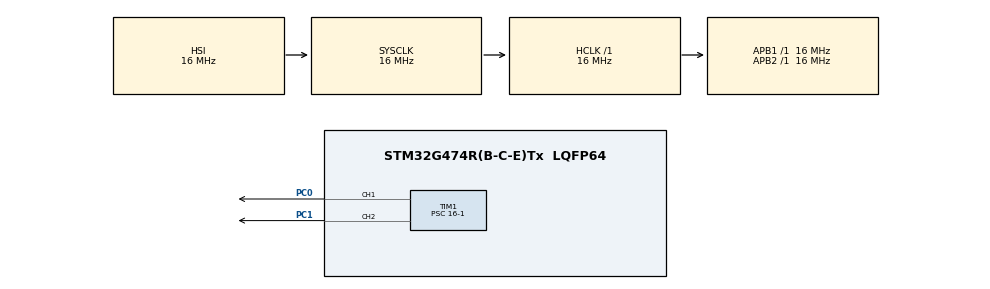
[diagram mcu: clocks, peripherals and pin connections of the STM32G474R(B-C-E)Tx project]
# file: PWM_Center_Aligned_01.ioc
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Mcu.Family=STM32G4
Mcu.Name=STM32G474R(B-C-E)Tx
Mcu.Package=LQFP64
NVIC.PriorityGroup=NVIC_PRIORITYGROUP_4
PC0.Signal=S_TIM1_CH1
PC1.Signal=S_TIM1_CH2
ProjectManager.HeapSize=0x200
ProjectManager.StackSize=0x400
ProjectManager.TargetToolchain=STM32CubeIDE
RCC.ADC12Freq_Value=16000000
RCC.ADC345Freq_Value=16000000
RCC.AHBFreq_Value=16000000
RCC.APB1Freq_Value=16000000
RCC.APB1TimFreq_Value=16000000
RCC.APB2Freq_Value=16000000
RCC.APB2TimFreq_Value=16000000
RCC.CortexFreq_Value=16000000
RCC.EXTERNAL_CLOCK_VALUE=12288000
RCC.HCLKFreq_Value=16000000
RCC.HSE_VALUE=24000000
RCC.HSI48_VALUE=48000000
RCC.HSI_VALUE=16000000
RCC.LSE_VALUE=32768
RCC.PLLM=RCC_PLLM_DIV4
RCC.PLLN=85
RCC.RTCClockSelection=RCC_RTCCLKSOURCE_LSE
RCC.SYSCLKFreq_VALUE=16000000
RCC.USBFreq_Value=170000000
RCC.VCOOutputFreq_Value=340000000
SH.S_TIM1_CH1.0=TIM1_CH1,PWM Generation1 CH1
SH.S_TIM1_CH2.0=TIM1_CH2,PWM Generation2 CH2
TIM1.AutoReloadPreload=TIM_AUTORELOAD_PRELOAD_ENABLE
TIM1.Channel-PWM\ Generation1\ CH1=TIM_CHANNEL_1
TIM1.Channel-PWM\ Generation2\ CH2=TIM_CHANNEL_2
TIM1.CounterMode=TIM_COUNTERMODE_CENTERALIGNED3
TIM1.PeriodNoDither=1000
TIM1.Prescaler=16-1
VP_SYS_VS_DBSignals.Mode=DisableDeadBatterySignals
VP_TIM1_VS_ClockSourceINT.Mode=Internal
board=NUCLEO-G474RE

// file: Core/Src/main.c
/* USER CODE BEGIN Header */
/**
  ******************************************************************************
  * @file           : main.c
  * @brief          : Main program body
  ******************************************************************************
  * @attention
  *
  * Copyright (c) 2026 STMicroelectronics.
  * All rights reserved.
  *
  * This software is licensed under terms that can be found in the LICENSE file
  * in the root directory of this software component.
  * If no LICENSE file comes with this software, it is provided AS-IS.
  *
  ******************************************************************************
	Hardware: NUCLEO-G474RE
	Objetivo: Alterar o alinhamento do PWM para o centro.

	Notas:
		Nas configurações do timer, selecione em "Counter Mode" a opção "Center Aligned mode3".
		E habilite o "auto-reload preload".

		f_tim_clk = 16 MHz
		PSC = 16-1 -> f_pwm = 1MHz
		ARR = 1000 -> f_pwm = f_pwm/(ARR/2) = 500Hz
		Conta até o valor de ARR.
  */
/* USER CODE END Header */
#include "main.h"

/* USER CODE BEGIN PD */
uint32_t dc1, dc2;
/* USER CODE END PD */

TIM_HandleTypeDef htim1;

void SystemClock_Config(void);
static void MX_GPIO_Init(void);
static void MX_TIM1_Init(void);

int main(void)
{

  /* MCU Configuration--------------------------------------------------------*/

  /* Reset of all peripherals, Initializes the Flash interface and the Systick. */
  HAL_Init();

  /* Configure the system clock */
  SystemClock_Config();

  /* Initialize all configured peripherals */
  MX_GPIO_Init();
  MX_TIM1_Init();
  /* USER CODE BEGIN 2 */

  // Inicializando o timer
  HAL_TIM_PWM_Start(&htim1, TIM_CHANNEL_1);
  HAL_TIM_PWM_Start(&htim1, TIM_CHANNEL_2);

  dc1 = 500;
  dc2 = dc2/2;

  /* USER CODE END 2 */

  /* Infinite loop */
  while (1)
  {

    /* USER CODE BEGIN 3 */
	  TIM1->CCR1 = dc1; // contador do canal 1
	  TIM1->CCR2 = dc2; // contador do canal 2

	  // Obs.: Atrubua valores as variaveis dc1 e dc2 pelo debug.
  }
  /* USER CODE END 3 */
}

void SystemClock_Config(void)
{
  RCC_OscInitTypeDef RCC_OscInitStruct = {0};
  RCC_ClkInitTypeDef RCC_ClkInitStruct = {0};

  /** Configure the main internal regulator output voltage
  */
  HAL_PWREx_ControlVoltageScaling(PWR_REGULATOR_VOLTAGE_SCALE1);

  /** Initializes the RCC Oscillators according to the specified parameters
  * in the RCC_OscInitTypeDef structure.
  */
  RCC_OscInitStruct.OscillatorType = RCC_OSCILLATORTYPE_HSI;
  RCC_OscInitStruct.HSIState = RCC_HSI_ON;
  RCC_OscInitStruct.HSICalibrationValue = RCC_HSICALIBRATION_DEFAULT;
  RCC_OscInitStruct.PLL.PLLState = RCC_PLL_NONE;
  if (HAL_RCC_OscConfig(&RCC_OscInitStruct) != HAL_OK)
  {
    Error_Handler();
  }

  /** Initializes the CPU, AHB and APB buses clocks
  */
  RCC_ClkInitStruct.ClockType = RCC_CLOCKTYPE_HCLK|RCC_CLOCKTYPE_SYSCLK
                              |RCC_CLOCKTYPE_PCLK1|RCC_CLOCKTYPE_PCLK2;
  RCC_ClkInitStruct.SYSCLKSource = RCC_SYSCLKSOURCE_HSI;
  RCC_ClkInitStruct.AHBCLKDivider = RCC_SYSCLK_DIV1;
  RCC_ClkInitStruct.APB1CLKDivider = RCC_HCLK_DIV1;
  RCC_ClkInitStruct.APB2CLKDivider = RCC_HCLK_DIV1;

  if (HAL_RCC_ClockConfig(&RCC_ClkInitStruct, FLASH_LATENCY_0) != HAL_OK)
  {
    Error_Handler();
  }
}

static void MX_TIM1_Init(void)
{

  TIM_ClockConfigTypeDef sClockSourceConfig = {0};
  TIM_MasterConfigTypeDef sMasterConfig = {0};
  TIM_OC_InitTypeDef sConfigOC = {0};
  TIM_BreakDeadTimeConfigTypeDef sBreakDeadTimeConfig = {0};

  htim1.Instance = TIM1;
  htim1.Init.Prescaler = 16-1;
  htim1.Init.CounterMode = TIM_COUNTERMODE_CENTERALIGNED3;
  htim1.Init.Period = 1000;
  htim1.Init.ClockDivision = TIM_CLOCKDIVISION_DIV1;
  htim1.Init.RepetitionCounter = 0;
  htim1.Init.AutoReloadPreload = TIM_AUTORELOAD_PRELOAD_ENABLE;
  if (HAL_TIM_Base_Init(&htim1) != HAL_OK)
  {
    Error_Handler();
  }
  sClockSourceConfig.ClockSource = TIM_CLOCKSOURCE_INTERNAL;
  if (HAL_TIM_ConfigClockSource(&htim1, &sClockSourceConfig) != HAL_OK)
  {
    Error_Handler();
  }
  if (HAL_TIM_PWM_Init(&htim1) != HAL_OK)
  {
    Error_Handler();
  }
  sMasterConfig.MasterOutputTrigger = TIM_TRGO_RESET;
  sMasterConfig.MasterOutputTrigger2 = TIM_TRGO2_RESET;
  sMasterConfig.MasterSlaveMode = TIM_MASTERSLAVEMODE_DISABLE;
  if (HAL_TIMEx_MasterConfigSynchronization(&htim1, &sMasterConfig) != HAL_OK)
  {
    Error_Handler();
  }
  sConfigOC.OCMode = TIM_OCMODE_PWM1;
  sConfigOC.Pulse = 0;
  sConfigOC.OCPolarity = TIM_OCPOLARITY_HIGH;
  sConfigOC.OCNPolarity = TIM_OCNPOLARITY_HIGH;
  sConfigOC.OCFastMode = TIM_OCFAST_DISABLE;
  sConfigOC.OCIdleState = TIM_OCIDLESTATE_RESET;
  sConfigOC.OCNIdleState = TIM_OCNIDLESTATE_RESET;
  if (HAL_TIM_PWM_ConfigChannel(&htim1, &sConfigOC, TIM_CHANNEL_1) != HAL_OK)
  {
    Error_Handler();
  }
  if (HAL_TIM_PWM_ConfigChannel(&htim1, &sConfigOC, TIM_CHANNEL_2) != HAL_OK)
  {
    Error_Handler();
  }
  sBreakDeadTimeConfig.OffStateRunMode = TIM_OSSR_DISABLE;
  sBreakDeadTimeConfig.OffStateIDLEMode = TIM_OSSI_DISABLE;
  sBreakDeadTimeConfig.LockLevel = TIM_LOCKLEVEL_OFF;
  sBreakDeadTimeConfig.DeadTime = 0;
  sBreakDeadTimeConfig.BreakState = TIM_BREAK_DISABLE;
  sBreakDeadTimeConfig.BreakPolarity = TIM_BREAKPOLARITY_HIGH;
  sBreakDeadTimeConfig.BreakFilter = 0;
  sBreakDeadTimeConfig.BreakAFMode = TIM_BREAK_AFMODE_INPUT;
  sBreakDeadTimeConfig.Break2State = TIM_BREAK2_DISABLE;
  sBreakDeadTimeConfig.Break2Polarity = TIM_BREAK2POLARITY_HIGH;
  sBreakDeadTimeConfig.Break2Filter = 0;
  sBreakDeadTimeConfig.Break2AFMode = TIM_BREAK_AFMODE_INPUT;
  sBreakDeadTimeConfig.AutomaticOutput = TIM_AUTOMATICOUTPUT_DISABLE;
  if (HAL_TIMEx_ConfigBreakDeadTime(&htim1, &sBreakDeadTimeConfig) != HAL_OK)
  {
    Error_Handler();
  }
  HAL_TIM_MspPostInit(&htim1);

}

static void MX_GPIO_Init(void)
{

  /* GPIO Ports Clock Enable */
  __HAL_RCC_GPIOC_CLK_ENABLE();

}

void Error_Handler(void)
{
  __disable_irq();
  while (1)
  {
  }
}
